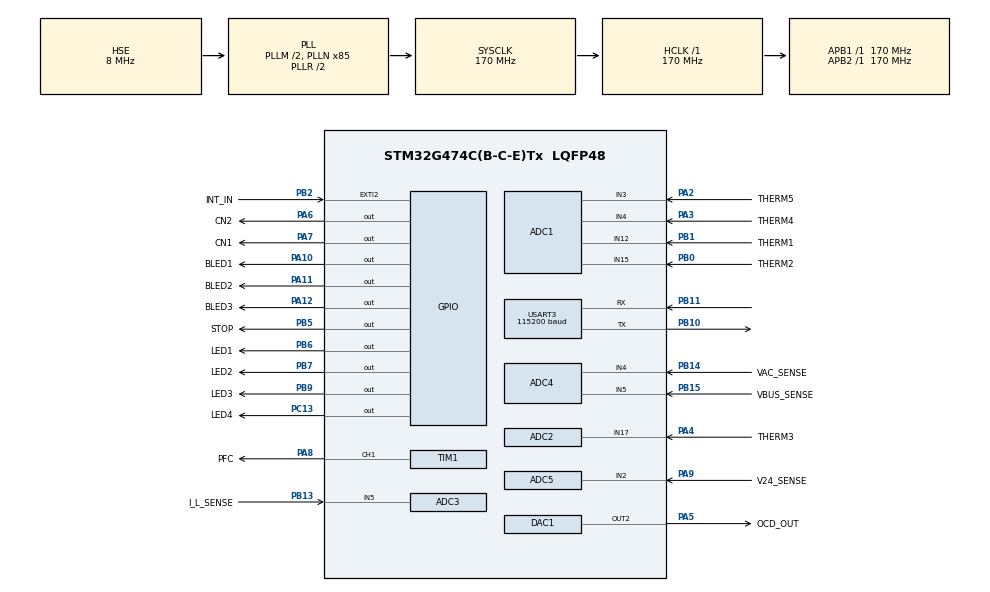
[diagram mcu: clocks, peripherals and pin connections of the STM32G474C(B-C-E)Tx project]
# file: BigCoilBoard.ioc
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ADC1.Channel-1\#ChannelRegularConversion=ADC_CHANNEL_12
ADC1.Channel-2\#ChannelRegularConversion=ADC_CHANNEL_15
ADC1.Channel-3\#ChannelRegularConversion=ADC_CHANNEL_4
ADC1.Channel-4\#ChannelRegularConversion=ADC_CHANNEL_3
ADC1.DMAContinuousRequests=ENABLE
ADC1.EOCSelection=ADC_EOC_SEQ_CONV
ADC1.ExternalTrigConv=ADC_EXTERNALTRIG_T6_TRGO
ADC1.NbrOfConversion=4
ADC1.NbrOfConversionFlag=1
ADC1.OffsetNumber-1\#ChannelRegularConversion=ADC_OFFSET_NONE
ADC1.OffsetNumber-2\#ChannelRegularConversion=ADC_OFFSET_NONE
ADC1.OffsetNumber-3\#ChannelRegularConversion=ADC_OFFSET_NONE
ADC1.OffsetNumber-4\#ChannelRegularConversion=ADC_OFFSET_NONE
ADC1.Rank-1\#ChannelRegularConversion=1
ADC1.Rank-2\#ChannelRegularConversion=2
ADC1.Rank-3\#ChannelRegularConversion=3
ADC1.Rank-4\#ChannelRegularConversion=4
ADC1.SamplingTime-1\#ChannelRegularConversion=ADC_SAMPLETIME_640CYCLES_5
ADC1.SamplingTime-2\#ChannelRegularConversion=ADC_SAMPLETIME_640CYCLES_5
ADC1.SamplingTime-3\#ChannelRegularConversion=ADC_SAMPLETIME_640CYCLES_5
ADC1.SamplingTime-4\#ChannelRegularConversion=ADC_SAMPLETIME_640CYCLES_5
ADC1.master=1
ADC2.Channel-2\#ChannelRegularConversion=ADC_CHANNEL_17
ADC2.DMAContinuousRequests=ENABLE
ADC2.ExternalTrigConv=ADC_EXTERNALTRIG_T6_TRGO
ADC2.NbrOfConversionFlag=1
ADC2.OffsetNumber-2\#ChannelRegularConversion=ADC_OFFSET_NONE
ADC2.Rank-2\#ChannelRegularConversion=1
ADC2.SamplingTime-2\#ChannelRegularConversion=ADC_SAMPLETIME_640CYCLES_5
ADC3.Channel-1\#ChannelRegularConversion=ADC_CHANNEL_5
ADC3.DMAContinuousRequests=ENABLE
ADC3.ExternalTrigConv=ADC_EXTERNALTRIG_T1_TRGO2
ADC3.NbrOfConversionFlag=1
ADC3.OffsetNumber-1\#ChannelRegularConversion=ADC_OFFSET_NONE
ADC3.Rank-1\#ChannelRegularConversion=1
ADC3.SamplingTime-1\#ChannelRegularConversion=ADC_SAMPLETIME_247CYCLES_5
ADC3.master=1
ADC4.Channel-1\#ChannelRegularConversion=ADC_CHANNEL_4
ADC4.Channel-2\#ChannelRegularConversion=ADC_CHANNEL_5
ADC4.DMAContinuousRequests=ENABLE
ADC4.ExternalTrigConv=ADC_EXTERNALTRIG_T1_TRGO2
ADC4.NbrOfConversion=2
ADC4.NbrOfConversionFlag=1
ADC4.OffsetNumber-1\#ChannelRegularConversion=ADC_OFFSET_NONE
ADC4.OffsetNumber-2\#ChannelRegularConversion=ADC_OFFSET_NONE
ADC4.Rank-1\#ChannelRegularConversion=1
ADC4.Rank-2\#ChannelRegularConversion=2
ADC4.SamplingTime-1\#ChannelRegularConversion=ADC_SAMPLETIME_247CYCLES_5
ADC4.SamplingTime-2\#ChannelRegularConversion=ADC_SAMPLETIME_247CYCLES_5
ADC5.Channel-0\#ChannelRegularConversion=ADC_CHANNEL_2
ADC5.Channel-1\#ChannelRegularConversion=ADC_CHANNEL_TEMPSENSOR_ADC5
ADC5.Channel-2\#ChannelRegularConversion=ADC_CHANNEL_VREFINT
ADC5.DMAContinuousRequests=ENABLE
ADC5.EOCSelection=ADC_EOC_SEQ_CONV
ADC5.ExternalTrigConv=ADC_EXTERNALTRIG_T6_TRGO
ADC5.NbrOfConversion=3
ADC5.NbrOfConversionFlag=1
ADC5.OffsetNumber-0\#ChannelRegularConversion=ADC_OFFSET_NONE
ADC5.OffsetNumber-1\#ChannelRegularConversion=ADC_OFFSET_NONE
ADC5.OffsetNumber-2\#ChannelRegularConversion=ADC_OFFSET_NONE
ADC5.Rank-0\#ChannelRegularConversion=1
ADC5.Rank-1\#ChannelRegularConversion=2
ADC5.Rank-2\#ChannelRegularConversion=3
ADC5.SamplingTime-0\#ChannelRegularConversion=ADC_SAMPLETIME_640CYCLES_5
ADC5.SamplingTime-1\#ChannelRegularConversion=ADC_SAMPLETIME_640CYCLES_5
ADC5.SamplingTime-2\#ChannelRegularConversion=ADC_SAMPLETIME_640CYCLES_5
COMP5.TriggerMode=COMP_TRIGGERMODE_IT_RISING
DAC1.DAC_Channel-DAC_OUT2=DAC_CHANNEL_2
DAC1.DAC_Trigger_OUT2-DAC_OUT2=DAC_TRIGGER_NONE
Dma.ADC1.0.Direction=DMA_PERIPH_TO_MEMORY
Dma.ADC1.0.EventEnable=DISABLE
Dma.ADC1.0.Instance=DMA1_Channel1
Dma.ADC1.0.MemDataAlignment=DMA_MDATAALIGN_HALFWORD
Dma.ADC1.0.MemInc=DMA_MINC_ENABLE
Dma.ADC1.0.Mode=DMA_CIRCULAR
Dma.ADC1.0.PeriphDataAlignment=DMA_PDATAALIGN_HALFWORD
Dma.ADC1.0.PeriphInc=DMA_PINC_DISABLE
Dma.ADC1.0.Polarity=HAL_DMAMUX_REQ_GEN_RISING
Dma.ADC1.0.Priority=DMA_PRIORITY_LOW
Dma.ADC1.0.RequestNumber=1
Dma.ADC1.0.SignalID=NONE
Dma.ADC1.0.SyncEnable=DISABLE
Dma.ADC1.0.SyncPolarity=HAL_DMAMUX_SYNC_NO_EVENT
Dma.ADC1.0.SyncRequestNumber=1
Dma.ADC1.0.SyncSignalID=NONE
Dma.ADC2.2.Direction=DMA_PERIPH_TO_MEMORY
Dma.ADC2.2.EventEnable=DISABLE
Dma.ADC2.2.Instance=DMA1_Channel2
Dma.ADC2.2.MemDataAlignment=DMA_MDATAALIGN_HALFWORD
Dma.ADC2.2.MemInc=DMA_MINC_ENABLE
Dma.ADC2.2.Mode=DMA_CIRCULAR
Dma.ADC2.2.PeriphDataAlignment=DMA_PDATAALIGN_HALFWORD
Dma.ADC2.2.PeriphInc=DMA_PINC_DISABLE
Dma.ADC2.2.Polarity=HAL_DMAMUX_REQ_GEN_RISING
Dma.ADC2.2.Priority=DMA_PRIORITY_LOW
Dma.ADC2.2.RequestNumber=1
Dma.ADC2.2.SignalID=NONE
Dma.ADC2.2.SyncEnable=DISABLE
Dma.ADC2.2.SyncPolarity=HAL_DMAMUX_SYNC_NO_EVENT
Dma.ADC2.2.SyncRequestNumber=1
Dma.ADC2.2.SyncSignalID=NONE
Dma.ADC3.3.Direction=DMA_PERIPH_TO_MEMORY
Dma.ADC3.3.EventEnable=DISABLE
Dma.ADC3.3.Instance=DMA1_Channel3
Dma.ADC3.3.MemDataAlignment=DMA_MDATAALIGN_HALFWORD
Dma.ADC3.3.MemInc=DMA_MINC_ENABLE
Dma.ADC3.3.Mode=DMA_CIRCULAR
Dma.ADC3.3.PeriphDataAlignment=DMA_PDATAALIGN_HALFWORD
Dma.ADC3.3.PeriphInc=DMA_PINC_DISABLE
Dma.ADC3.3.Polarity=HAL_DMAMUX_REQ_GEN_RISING
Dma.ADC3.3.Priority=DMA_PRIORITY_LOW
Dma.ADC3.3.RequestNumber=1
Dma.ADC3.3.SignalID=NONE
Dma.ADC3.3.SyncEnable=DISABLE
Dma.ADC3.3.SyncPolarity=HAL_DMAMUX_SYNC_NO_EVENT
Dma.ADC3.3.SyncRequestNumber=1
Dma.ADC3.3.SyncSignalID=NONE
Dma.ADC4.4.Direction=DMA_PERIPH_TO_MEMORY
Dma.ADC4.4.EventEnable=DISABLE
Dma.ADC4.4.Instance=DMA1_Channel4
Dma.ADC4.4.MemDataAlignment=DMA_MDATAALIGN_HALFWORD
Dma.ADC4.4.MemInc=DMA_MINC_ENABLE
Dma.ADC4.4.Mode=DMA_CIRCULAR
Dma.ADC4.4.PeriphDataAlignment=DMA_PDATAALIGN_HALFWORD
Dma.ADC4.4.PeriphInc=DMA_PINC_DISABLE
Dma.ADC4.4.Polarity=HAL_DMAMUX_REQ_GEN_RISING
Dma.ADC4.4.Priority=DMA_PRIORITY_LOW
Dma.ADC4.4.RequestNumber=1
Dma.ADC4.4.SignalID=NONE
Dma.ADC4.4.SyncEnable=DISABLE
Dma.ADC4.4.SyncPolarity=HAL_DMAMUX_SYNC_NO_EVENT
Dma.ADC4.4.SyncRequestNumber=1
Dma.ADC4.4.SyncSignalID=NONE
Dma.ADC5.1.Direction=DMA_PERIPH_TO_MEMORY
Dma.ADC5.1.EventEnable=DISABLE
Dma.ADC5.1.Instance=DMA1_Channel6
Dma.ADC5.1.MemDataAlignment=DMA_MDATAALIGN_HALFWORD
Dma.ADC5.1.MemInc=DMA_MINC_ENABLE
Dma.ADC5.1.Mode=DMA_CIRCULAR
Dma.ADC5.1.PeriphDataAlignment=DMA_PDATAALIGN_HALFWORD
Dma.ADC5.1.PeriphInc=DMA_PINC_DISABLE
Dma.ADC5.1.Polarity=HAL_DMAMUX_REQ_GEN_RISING
Dma.ADC5.1.Priority=DMA_PRIORITY_LOW
Dma.ADC5.1.RequestNumber=1
Dma.ADC5.1.SignalID=NONE
Dma.ADC5.1.SyncEnable=DISABLE
Dma.ADC5.1.SyncPolarity=HAL_DMAMUX_SYNC_NO_EVENT
Dma.ADC5.1.SyncRequestNumber=1
Dma.ADC5.1.SyncSignalID=NONE
Dma.Request0=ADC1
Dma.Request1=ADC5
Dma.Request2=ADC2
Dma.Request3=ADC3
Dma.Request4=ADC4
Mcu.Family=STM32G4
Mcu.Name=STM32G474C(B-C-E)Tx
Mcu.Package=LQFP48
NVIC.ADC1_2_IRQn=true\:0\:0\:true\:false\:true\:true\:true\:true
NVIC.ADC3_IRQn=true\:0\:0\:true\:false\:true\:true\:true\:true
NVIC.ADC4_IRQn=true\:0\:0\:false\:false\:true\:true\:true\:true
NVIC.ADC5_IRQn=true\:0\:0\:false\:false\:true\:true\:true\:true
NVIC.COMP4_5_6_IRQn=true\:0\:0\:false\:false\:true\:false\:true\:true
NVIC.DMA1_Channel1_IRQn=true\:0\:0\:false\:false\:true\:false\:true\:true
NVIC.DMA1_Channel2_IRQn=true\:0\:0\:false\:false\:true\:false\:true\:true
NVIC.DMA1_Channel3_IRQn=true\:0\:0\:false\:false\:true\:false\:true\:true
NVIC.DMA1_Channel4_IRQn=true\:0\:0\:false\:false\:true\:false\:true\:true
NVIC.DMA1_Channel6_IRQn=true\:0\:0\:false\:false\:true\:false\:true\:true
NVIC.EXTI2_IRQn=true\:0\:0\:false\:false\:true\:true\:true\:true
NVIC.FLASH_IRQn=true\:0\:0\:false\:false\:true\:true\:true\:true
NVIC.FPU_IRQn=true\:0\:0\:false\:false\:true\:true\:false\:true
NVIC.PriorityGroup=NVIC_PRIORITYGROUP_4
NVIC.RCC_IRQn=true\:0\:0\:false\:false\:true\:true\:false\:true
NVIC.TIM1_BRK_TIM15_IRQn=true\:0\:0\:true\:false\:true\:true\:true\:true
NVIC.TIM1_CC_IRQn=true\:0\:0\:true\:false\:true\:true\:true\:true
NVIC.TIM1_TRG_COM_TIM17_IRQn=true\:0\:0\:true\:false\:true\:true\:true\:true
NVIC.TIM1_UP_TIM16_IRQn=true\:0\:0\:true\:false\:true\:true\:true\:true
NVIC.TIM2_IRQn=true\:0\:0\:true\:false\:true\:true\:true\:true
NVIC.TIM6_DAC_IRQn=true\:0\:0\:true\:false\:true\:true\:true\:true
NVIC.TIM7_DAC_IRQn=true\:0\:0\:true\:false\:true\:true\:true\:true
NVIC.USART3_IRQn=true\:0\:0\:true\:false\:true\:true\:true\:true
PA10.GPIO_Label=BLED1
PA10.Signal=GPIO_Output
PA11.GPIO_Label=BLED2
PA11.Signal=GPIO_Output
PA12.GPIO_Label=BLED3
PA12.Signal=GPIO_Output
PA13.Mode=JTAG_4_pins
PA13.Signal=SYS_JTMS-SWDIO
PA14.Mode=JTAG_4_pins
PA14.Signal=SYS_JTCK-SWCLK
PA15.Mode=JTAG_4_pins
PA15.Signal=SYS_JTDI
PA2.GPIO_Label=THERM5
PA2.Mode=IN3-Single-Ended
PA2.Signal=ADC1_IN3
PA3.GPIO_Label=THERM4
PA3.Mode=IN4-Single-Ended
PA3.Signal=ADC1_IN4
PA4.GPIO_Label=THERM3
PA4.Mode=IN17-Single-Ended
PA4.Signal=ADC2_IN17
PA5.GPIO_Label=OCD_OUT
PA5.Signal=COMP_DAC12_group
PA6.GPIO_Label=CN2
PA6.Signal=GPIO_Output
PA7.GPIO_Label=CN1
PA7.Signal=GPIO_Output
PA8.GPIO_Label=PFC
PA8.Signal=S_TIM1_CH1
PA9.GPIO_Label=V24_SENSE
PA9.Mode=IN2-Single-Ended
PA9.Signal=ADC5_IN2
PB0.GPIO_Label=THERM2
PB0.Mode=IN15-Single-Ended
PB0.Signal=ADC1_IN15
PB1.GPIO_Label=THERM1
PB1.Mode=IN12-Single-Ended
PB1.Signal=ADC1_IN12
PB10.Mode=Asynchronous
PB10.Signal=USART3_TX
PB11.Mode=Asynchronous
PB11.Signal=USART3_RX
PB13.GPIO_Label=I_L_SENSE
PB13.Signal=SharedAnalog_PB13
PB14.GPIO_Label=VAC_SENSE
PB14.Mode=IN4-Single-Ended
PB14.Signal=ADC4_IN4
PB15.GPIO_Label=VBUS_SENSE
PB15.Mode=IN5-Single-Ended
PB15.Signal=ADC4_IN5
PB2.GPIO_Label=INT_IN
PB2.Signal=GPXTI2
PB3.Mode=JTAG_4_pins
PB3.Signal=SYS_JTDO-SWO
PB4.Signal=SYS_JTRST
PB5.GPIO_Label=STOP
PB5.Signal=GPIO_Output
PB6.GPIO_Label=LED1
PB6.Signal=GPIO_Output
PB7.GPIO_Label=LED2
PB7.Signal=GPIO_Output
PB9.GPIO_Label=LED3
PB9.Signal=GPIO_Output
PC13.GPIO_Label=LED4
PC13.Signal=GPIO_Output
PF0-OSC_IN.Mode=HSE-External-Oscillator
PF0-OSC_IN.Signal=RCC_OSC_IN
PF1-OSC_OUT.Mode=HSE-External-Oscillator
PF1-OSC_OUT.Signal=RCC_OSC_OUT
ProjectManager.HeapSize=0x200
ProjectManager.StackSize=0x400
ProjectManager.TargetToolchain=STM32CubeIDE
RCC.ADC12Freq_Value=170000000
RCC.ADC345Freq_Value=170000000
RCC.AHBFreq_Value=170000000
RCC.APB1Freq_Value=170000000
RCC.APB1TimFreq_Value=170000000
RCC.APB2Freq_Value=170000000
RCC.APB2TimFreq_Value=170000000
RCC.CortexFreq_Value=170000000
RCC.EXTERNAL_CLOCK_VALUE=12288000
RCC.HCLKFreq_Value=170000000
RCC.HSE_VALUE=8000000
RCC.HSI48_VALUE=48000000
RCC.HSI_VALUE=16000000
RCC.LSE_VALUE=32768
RCC.PLLM=RCC_PLLM_DIV2
RCC.PLLN=85
RCC.PLLSourceVirtual=RCC_PLLSOURCE_HSE
RCC.SYSCLKFreq_VALUE=170000000
RCC.SYSCLKSource=RCC_SYSCLKSOURCE_PLLCLK
RCC.USBFreq_Value=170000000
RCC.VCOOutputFreq_Value=340000000
SH.COMP_DAC12_group.0=DAC1_OUT2,DAC_OUT2
SH.S_TIM1_CH1.0=TIM1_CH1,PWM Generation1 CH1
SH.SharedAnalog_PB13.0=ADC3_IN5,IN5-Single-Ended
SH.SharedAnalog_PB13.1=COMP5_INP,INP
TIM1.BreakState=TIM_BREAK_DISABLE
TIM1.Channel-PWM\ Generation1\ CH1=TIM_CHANNEL_1
TIM1.Channel-PWM\ Generation5\ No\ Output=TIM_CHANNEL_5
TIM1.CounterMode=TIM_COUNTERMODE_CENTERALIGNED1
TIM1.PeriodNoDither=9444
TIM1.PulseNoDither_5=1
TIM1.SourceBRKCOMP5=TIM_BREAKINPUTSOURCE_ENABLE
TIM1.TIM_MasterOutputTrigger=TIM_TRGO_UPDATE
TIM1.TIM_MasterOutputTrigger2=TIM_TRGO2_OC5REF
TIM16.Prescaler=170
TIM2.Prescaler=0
TIM2.TIM_MasterOutputTrigger=TIM_TRGO_UPDATE
TIM6.PeriodNoDither=10000
TIM6.Prescaler=170
TIM6.TIM_MasterOutputTrigger=TIM_TRGO_UPDATE
TIM7.PeriodNoDither=1360
TIM7.Prescaler=50000
TIM7.TIM_MasterOutputTrigger=TIM_TRGO_UPDATE
USART3.BaudRate=115200
USART3.RxPinLevelInvertParam=ADVFEATURE_RXINV_DISABLE
USART3.VirtualMode-Asynchronous=VM_ASYNC
VP_ADC5_TempSens_Input.Mode=IN-TempSens
VP_ADC5_Vref_Input.Mode=IN-Vrefint
VP_COMP5_VS_DAC4OUT1.Mode=INM_DAC4OUT1
VP_DAC4_VS_DACI1.Mode=DAC_OUT1_Int
VP_SYS_VS_DBSignals.Mode=DisableDeadBatterySignals
VP_SYS_V_VREFBUF.Mode=ExternalMode
VP_TIM16_VS_ClockSourceINT.Mode=Enable_Timer
VP_TIM1_VS_ClockSourceINT.Mode=Internal
VP_TIM1_VS_no_output5.Mode=PWM Generation5 No Output
VP_TIM2_VS_ClockSourceINT.Mode=Internal
VP_TIM6_VS_ClockSourceINT.Mode=Enable_Timer
VP_TIM7_VS_ClockSourceINT.Mode=Enable_Timer
board=custom

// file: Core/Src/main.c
/* USER CODE BEGIN Header */
/**
  ******************************************************************************
  * @file           : main.c
  * @brief          : Main program body
  ******************************************************************************
  * @attention
  *
  * Copyright (c) 2025 STMicroelectronics.
  * All rights reserved.
  *
  * This software is licensed under terms that can be found in the LICENSE file
  * in the root directory of this software component.
  * If no LICENSE file comes with this software, it is provided AS-IS.
  *
  ******************************************************************************
  */
/* USER CODE END Header */
#include "main.h"

ADC_HandleTypeDef hadc1;
ADC_HandleTypeDef hadc2;
ADC_HandleTypeDef hadc3;
ADC_HandleTypeDef hadc4;
ADC_HandleTypeDef hadc5;
DMA_HandleTypeDef hdma_adc1;
DMA_HandleTypeDef hdma_adc2;
DMA_HandleTypeDef hdma_adc3;
DMA_HandleTypeDef hdma_adc4;
DMA_HandleTypeDef hdma_adc5;

COMP_HandleTypeDef hcomp5;

DAC_HandleTypeDef hdac1;
DAC_HandleTypeDef hdac4;

TIM_HandleTypeDef htim1;
TIM_HandleTypeDef htim2;
TIM_HandleTypeDef htim6;
TIM_HandleTypeDef htim7;
TIM_HandleTypeDef htim16;

UART_HandleTypeDef huart3;

void SystemClock_Config(void);
static void MX_GPIO_Init(void);
static void MX_DMA_Init(void);
static void MX_DAC1_Init(void);
static void MX_USART3_UART_Init(void);
static void MX_TIM6_Init(void);
static void MX_TIM7_Init(void);
static void MX_TIM1_Init(void);
static void MX_ADC1_Init(void);
static void MX_TIM2_Init(void);
static void MX_TIM16_Init(void);
static void MX_ADC5_Init(void);
static void MX_ADC2_Init(void);
static void MX_DAC4_Init(void);
static void MX_ADC3_Init(void);
static void MX_ADC4_Init(void);
static void MX_COMP5_Init(void);

int main(void)
{

  /* MCU Configuration--------------------------------------------------------*/

  /* Reset of all peripherals, Initializes the Flash interface and the Systick. */
  HAL_Init();

  /* Configure the system clock */
  SystemClock_Config();

  /* Initialize all configured peripherals */
  MX_GPIO_Init();
  MX_DMA_Init();
  MX_DAC1_Init();
  MX_USART3_UART_Init();
  MX_TIM6_Init();
  MX_TIM7_Init();
  MX_TIM1_Init();
  MX_ADC1_Init();
  MX_TIM2_Init();
  MX_TIM16_Init();
  MX_ADC5_Init();
  MX_ADC2_Init();
  MX_DAC4_Init();
  MX_ADC3_Init();
  MX_ADC4_Init();
  MX_COMP5_Init();
  /* USER CODE BEGIN 2 */
  TC_Init();
  /* USER CODE END 2 */

  /* Infinite loop */
  while (1)
  {

    /* USER CODE BEGIN 3 */
	  TC_Loop();
  }
  /* USER CODE END 3 */
}

void SystemClock_Config(void)
{
  RCC_OscInitTypeDef RCC_OscInitStruct = {0};
  RCC_ClkInitTypeDef RCC_ClkInitStruct = {0};

  /** Configure the main internal regulator output voltage
  */
  HAL_PWREx_ControlVoltageScaling(PWR_REGULATOR_VOLTAGE_SCALE1_BOOST);

  /** Initializes the RCC Oscillators according to the specified parameters
  * in the RCC_OscInitTypeDef structure.
  */
  RCC_OscInitStruct.OscillatorType = RCC_OSCILLATORTYPE_HSE;
  RCC_OscInitStruct.HSEState = RCC_HSE_ON;
  RCC_OscInitStruct.PLL.PLLState = RCC_PLL_ON;
  RCC_OscInitStruct.PLL.PLLSource = RCC_PLLSOURCE_HSE;
  RCC_OscInitStruct.PLL.PLLM = RCC_PLLM_DIV2;
  RCC_OscInitStruct.PLL.PLLN = 85;
  RCC_OscInitStruct.PLL.PLLP = RCC_PLLP_DIV2;
  RCC_OscInitStruct.PLL.PLLQ = RCC_PLLQ_DIV2;
  RCC_OscInitStruct.PLL.PLLR = RCC_PLLR_DIV2;
  if (HAL_RCC_OscConfig(&RCC_OscInitStruct) != HAL_OK)
  {
    Error_Handler();
  }

  /** Initializes the CPU, AHB and APB buses clocks
  */
  RCC_ClkInitStruct.ClockType = RCC_CLOCKTYPE_HCLK|RCC_CLOCKTYPE_SYSCLK
                              |RCC_CLOCKTYPE_PCLK1|RCC_CLOCKTYPE_PCLK2;
  RCC_ClkInitStruct.SYSCLKSource = RCC_SYSCLKSOURCE_PLLCLK;
  RCC_ClkInitStruct.AHBCLKDivider = RCC_SYSCLK_DIV1;
  RCC_ClkInitStruct.APB1CLKDivider = RCC_HCLK_DIV1;
  RCC_ClkInitStruct.APB2CLKDivider = RCC_HCLK_DIV1;

  if (HAL_RCC_ClockConfig(&RCC_ClkInitStruct, FLASH_LATENCY_4) != HAL_OK)
  {
    Error_Handler();
  }
}

static void MX_ADC1_Init(void)
{

  ADC_MultiModeTypeDef multimode = {0};
  ADC_ChannelConfTypeDef sConfig = {0};

  /** Common config
  */
  hadc1.Instance = ADC1;
  hadc1.Init.ClockPrescaler = ADC_CLOCK_SYNC_PCLK_DIV4;
  hadc1.Init.Resolution = ADC_RESOLUTION_12B;
  hadc1.Init.DataAlign = ADC_DATAALIGN_RIGHT;
  hadc1.Init.GainCompensation = 0;
  hadc1.Init.ScanConvMode = ADC_SCAN_ENABLE;
  hadc1.Init.EOCSelection = ADC_EOC_SEQ_CONV;
  hadc1.Init.LowPowerAutoWait = DISABLE;
  hadc1.Init.ContinuousConvMode = DISABLE;
  hadc1.Init.NbrOfConversion = 4;
  hadc1.Init.DiscontinuousConvMode = DISABLE;
  hadc1.Init.ExternalTrigConv = ADC_EXTERNALTRIG_T6_TRGO;
  hadc1.Init.ExternalTrigConvEdge = ADC_EXTERNALTRIGCONVEDGE_RISING;
  hadc1.Init.DMAContinuousRequests = ENABLE;
  hadc1.Init.Overrun = ADC_OVR_DATA_PRESERVED;
  hadc1.Init.OversamplingMode = DISABLE;
  if (HAL_ADC_Init(&hadc1) != HAL_OK)
  {
    Error_Handler();
  }

  /** Configure the ADC multi-mode
  */
  multimode.Mode = ADC_MODE_INDEPENDENT;
  if (HAL_ADCEx_MultiModeConfigChannel(&hadc1, &multimode) != HAL_OK)
  {
    Error_Handler();
  }

  /** Configure Regular Channel
  */
  sConfig.Channel = ADC_CHANNEL_12;
  sConfig.Rank = ADC_REGULAR_RANK_1;
  sConfig.SamplingTime = ADC_SAMPLETIME_640CYCLES_5;
  sConfig.SingleDiff = ADC_SINGLE_ENDED;
  sConfig.OffsetNumber = ADC_OFFSET_NONE;
  sConfig.Offset = 0;
  if (HAL_ADC_ConfigChannel(&hadc1, &sConfig) != HAL_OK)
  {
    Error_Handler();
  }

  /** Configure Regular Channel
  */
  sConfig.Channel = ADC_CHANNEL_15;
  sConfig.Rank = ADC_REGULAR_RANK_2;
  if (HAL_ADC_ConfigChannel(&hadc1, &sConfig) != HAL_OK)
  {
    Error_Handler();
  }

  /** Configure Regular Channel
  */
  sConfig.Channel = ADC_CHANNEL_4;
  sConfig.Rank = ADC_REGULAR_RANK_3;
  if (HAL_ADC_ConfigChannel(&hadc1, &sConfig) != HAL_OK)
  {
    Error_Handler();
  }

  /** Configure Regular Channel
  */
  sConfig.Channel = ADC_CHANNEL_3;
  sConfig.Rank = ADC_REGULAR_RANK_4;
  if (HAL_ADC_ConfigChannel(&hadc1, &sConfig) != HAL_OK)
  {
    Error_Handler();
  }

}

static void MX_ADC2_Init(void)
{

  ADC_ChannelConfTypeDef sConfig = {0};

  /** Common config
  */
  hadc2.Instance = ADC2;
  hadc2.Init.ClockPrescaler = ADC_CLOCK_SYNC_PCLK_DIV4;
  hadc2.Init.Resolution = ADC_RESOLUTION_12B;
  hadc2.Init.DataAlign = ADC_DATAALIGN_RIGHT;
  hadc2.Init.GainCompensation = 0;
  hadc2.Init.ScanConvMode = ADC_SCAN_DISABLE;
  hadc2.Init.EOCSelection = ADC_EOC_SINGLE_CONV;
  hadc2.Init.LowPowerAutoWait = DISABLE;
  hadc2.Init.ContinuousConvMode = DISABLE;
  hadc2.Init.NbrOfConversion = 1;
  hadc2.Init.DiscontinuousConvMode = DISABLE;
  hadc2.Init.ExternalTrigConv = ADC_EXTERNALTRIG_T6_TRGO;
  hadc2.Init.ExternalTrigConvEdge = ADC_EXTERNALTRIGCONVEDGE_RISING;
  hadc2.Init.DMAContinuousRequests = ENABLE;
  hadc2.Init.Overrun = ADC_OVR_DATA_PRESERVED;
  hadc2.Init.OversamplingMode = DISABLE;
  if (HAL_ADC_Init(&hadc2) != HAL_OK)
  {
    Error_Handler();
  }

  /** Configure Regular Channel
  */
  sConfig.Channel = ADC_CHANNEL_17;
  sConfig.Rank = ADC_REGULAR_RANK_1;
  sConfig.SamplingTime = ADC_SAMPLETIME_640CYCLES_5;
  sConfig.SingleDiff = ADC_SINGLE_ENDED;
  sConfig.OffsetNumber = ADC_OFFSET_NONE;
  sConfig.Offset = 0;
  if (HAL_ADC_ConfigChannel(&hadc2, &sConfig) != HAL_OK)
  {
    Error_Handler();
  }

}

static void MX_ADC3_Init(void)
{

  ADC_MultiModeTypeDef multimode = {0};
  ADC_ChannelConfTypeDef sConfig = {0};

  /** Common config
  */
  hadc3.Instance = ADC3;
  hadc3.Init.ClockPrescaler = ADC_CLOCK_SYNC_PCLK_DIV4;
  hadc3.Init.Resolution = ADC_RESOLUTION_12B;
  hadc3.Init.DataAlign = ADC_DATAALIGN_RIGHT;
  hadc3.Init.GainCompensation = 0;
  hadc3.Init.ScanConvMode = ADC_SCAN_DISABLE;
  hadc3.Init.EOCSelection = ADC_EOC_SINGLE_CONV;
  hadc3.Init.LowPowerAutoWait = DISABLE;
  hadc3.Init.ContinuousConvMode = DISABLE;
  hadc3.Init.NbrOfConversion = 1;
  hadc3.Init.DiscontinuousConvMode = DISABLE;
  hadc3.Init.ExternalTrigConv = ADC_EXTERNALTRIG_T1_TRGO2;
  hadc3.Init.ExternalTrigConvEdge = ADC_EXTERNALTRIGCONVEDGE_RISING;
  hadc3.Init.DMAContinuousRequests = ENABLE;
  hadc3.Init.Overrun = ADC_OVR_DATA_PRESERVED;
  hadc3.Init.OversamplingMode = DISABLE;
  if (HAL_ADC_Init(&hadc3) != HAL_OK)
  {
    Error_Handler();
  }

  /** Configure the ADC multi-mode
  */
  multimode.Mode = ADC_MODE_INDEPENDENT;
  if (HAL_ADCEx_MultiModeConfigChannel(&hadc3, &multimode) != HAL_OK)
  {
    Error_Handler();
  }

  /** Configure Regular Channel
  */
  sConfig.Channel = ADC_CHANNEL_5;
  sConfig.Rank = ADC_REGULAR_RANK_1;
  sConfig.SamplingTime = ADC_SAMPLETIME_247CYCLES_5;
  sConfig.SingleDiff = ADC_SINGLE_ENDED;
  sConfig.OffsetNumber = ADC_OFFSET_NONE;
  sConfig.Offset = 0;
  if (HAL_ADC_ConfigChannel(&hadc3, &sConfig) != HAL_OK)
  {
    Error_Handler();
  }

}

static void MX_ADC4_Init(void)
{

  ADC_ChannelConfTypeDef sConfig = {0};

  /** Common config
  */
  hadc4.Instance = ADC4;
  hadc4.Init.ClockPrescaler = ADC_CLOCK_SYNC_PCLK_DIV4;
  hadc4.Init.Resolution = ADC_RESOLUTION_12B;
  hadc4.Init.DataAlign = ADC_DATAALIGN_RIGHT;
  hadc4.Init.GainCompensation = 0;
  hadc4.Init.ScanConvMode = ADC_SCAN_ENABLE;
  hadc4.Init.EOCSelection = ADC_EOC_SINGLE_CONV;
  hadc4.Init.LowPowerAutoWait = DISABLE;
  hadc4.Init.ContinuousConvMode = DISABLE;
  hadc4.Init.NbrOfConversion = 2;
  hadc4.Init.DiscontinuousConvMode = DISABLE;
  hadc4.Init.ExternalTrigConv = ADC_EXTERNALTRIG_T1_TRGO2;
  hadc4.Init.ExternalTrigConvEdge = ADC_EXTERNALTRIGCONVEDGE_RISING;
  hadc4.Init.DMAContinuousRequests = ENABLE;
  hadc4.Init.Overrun = ADC_OVR_DATA_PRESERVED;
  hadc4.Init.OversamplingMode = DISABLE;
  if (HAL_ADC_Init(&hadc4) != HAL_OK)
  {
    Error_Handler();
  }

  /** Configure Regular Channel
  */
  sConfig.Channel = ADC_CHANNEL_4;
  sConfig.Rank = ADC_REGULAR_RANK_1;
  sConfig.SamplingTime = ADC_SAMPLETIME_247CYCLES_5;
  sConfig.SingleDiff = ADC_SINGLE_ENDED;
  sConfig.OffsetNumber = ADC_OFFSET_NONE;
  sConfig.Offset = 0;
  if (HAL_ADC_ConfigChannel(&hadc4, &sConfig) != HAL_OK)
  {
    Error_Handler();
  }

  /** Configure Regular Channel
  */
  sConfig.Channel = ADC_CHANNEL_5;
  sConfig.Rank = ADC_REGULAR_RANK_2;
  if (HAL_ADC_ConfigChannel(&hadc4, &sConfig) != HAL_OK)
  {
    Error_Handler();
  }

}

static void MX_ADC5_Init(void)
{

  ADC_ChannelConfTypeDef sConfig = {0};

  /** Common config
  */
  hadc5.Instance = ADC5;
  hadc5.Init.ClockPrescaler = ADC_CLOCK_SYNC_PCLK_DIV4;
  hadc5.Init.Resolution = ADC_RESOLUTION_12B;
  hadc5.Init.DataAlign = ADC_DATAALIGN_RIGHT;
  hadc5.Init.GainCompensation = 0;
  hadc5.Init.ScanConvMode = ADC_SCAN_ENABLE;
  hadc5.Init.EOCSelection = ADC_EOC_SEQ_CONV;
  hadc5.Init.LowPowerAutoWait = DISABLE;
  hadc5.Init.ContinuousConvMode = DISABLE;
  hadc5.Init.NbrOfConversion = 3;
  hadc5.Init.DiscontinuousConvMode = DISABLE;
  hadc5.Init.ExternalTrigConv = ADC_EXTERNALTRIG_T6_TRGO;
  hadc5.Init.ExternalTrigConvEdge = ADC_EXTERNALTRIGCONVEDGE_RISING;
  hadc5.Init.DMAContinuousRequests = ENABLE;
  hadc5.Init.Overrun = ADC_OVR_DATA_PRESERVED;
  hadc5.Init.OversamplingMode = DISABLE;
  if (HAL_ADC_Init(&hadc5) != HAL_OK)
  {
    Error_Handler();
  }

  /** Configure Regular Channel
  */
  sConfig.Channel = ADC_CHANNEL_2;
  sConfig.Rank = ADC_REGULAR_RANK_1;
  sConfig.SamplingTime = ADC_SAMPLETIME_640CYCLES_5;
  sConfig.SingleDiff = ADC_SINGLE_ENDED;
  sConfig.OffsetNumber = ADC_OFFSET_NONE;
  sConfig.Offset = 0;
  if (HAL_ADC_ConfigChannel(&hadc5, &sConfig) != HAL_OK)
  {
    Error_Handler();
  }

  /** Configure Regular Channel
  */
  sConfig.Channel = ADC_CHANNEL_TEMPSENSOR_ADC5;
  sConfig.Rank = ADC_REGULAR_RANK_2;
  if (HAL_ADC_ConfigChannel(&hadc5, &sConfig) != HAL_OK)
  {
    Error_Handler();
  }

  /** Configure Regular Channel
  */
  sConfig.Channel = ADC_CHANNEL_VREFINT;
  sConfig.Rank = ADC_REGULAR_RANK_3;
  if (HAL_ADC_ConfigChannel(&hadc5, &sConfig) != HAL_OK)
  {
    Error_Handler();
  }

}

static void MX_COMP5_Init(void)
{

  hcomp5.Instance = COMP5;
  hcomp5.Init.InputPlus = COMP_INPUT_PLUS_IO1;
  hcomp5.Init.InputMinus = COMP_INPUT_MINUS_DAC4_CH1;
  hcomp5.Init.OutputPol = COMP_OUTPUTPOL_NONINVERTED;
  hcomp5.Init.Hysteresis = COMP_HYSTERESIS_NONE;
  hcomp5.Init.BlankingSrce = COMP_BLANKINGSRC_NONE;
  hcomp5.Init.TriggerMode = COMP_TRIGGERMODE_IT_RISING;
  if (HAL_COMP_Init(&hcomp5) != HAL_OK)
  {
    Error_Handler();
  }

}

static void MX_DAC1_Init(void)
{

  DAC_ChannelConfTypeDef sConfig = {0};

  /** DAC Initialization
  */
  hdac1.Instance = DAC1;
  if (HAL_DAC_Init(&hdac1) != HAL_OK)
  {
    Error_Handler();
  }

  /** DAC channel OUT2 config
  */
  sConfig.DAC_HighFrequency = DAC_HIGH_FREQUENCY_INTERFACE_MODE_AUTOMATIC;
  sConfig.DAC_DMADoubleDataMode = DISABLE;
  sConfig.DAC_SignedFormat = DISABLE;
  sConfig.DAC_SampleAndHold = DAC_SAMPLEANDHOLD_DISABLE;
  sConfig.DAC_Trigger = DAC_TRIGGER_NONE;
  sConfig.DAC_Trigger2 = DAC_TRIGGER_NONE;
  sConfig.DAC_OutputBuffer = DAC_OUTPUTBUFFER_ENABLE;
  sConfig.DAC_ConnectOnChipPeripheral = DAC_CHIPCONNECT_EXTERNAL;
  sConfig.DAC_UserTrimming = DAC_TRIMMING_FACTORY;
  if (HAL_DAC_ConfigChannel(&hdac1, &sConfig, DAC_CHANNEL_2) != HAL_OK)
  {
    Error_Handler();
  }

}

static void MX_DAC4_Init(void)
{

  DAC_ChannelConfTypeDef sConfig = {0};

  /** DAC Initialization
  */
  hdac4.Instance = DAC4;
  if (HAL_DAC_Init(&hdac4) != HAL_OK)
  {
    Error_Handler();
  }

  /** DAC channel OUT1 config
  */
  sConfig.DAC_HighFrequency = DAC_HIGH_FREQUENCY_INTERFACE_MODE_AUTOMATIC;
  sConfig.DAC_DMADoubleDataMode = DISABLE;
  sConfig.DAC_SignedFormat = DISABLE;
  sConfig.DAC_SampleAndHold = DAC_SAMPLEANDHOLD_DISABLE;
  sConfig.DAC_Trigger = DAC_TRIGGER_NONE;
  sConfig.DAC_Trigger2 = DAC_TRIGGER_NONE;
  sConfig.DAC_OutputBuffer = DAC_OUTPUTBUFFER_DISABLE;
  sConfig.DAC_ConnectOnChipPeripheral = DAC_CHIPCONNECT_INTERNAL;
  sConfig.DAC_UserTrimming = DAC_TRIMMING_FACTORY;
  if (HAL_DAC_ConfigChannel(&hdac4, &sConfig, DAC_CHANNEL_1) != HAL_OK)
  {
    Error_Handler();
  }

}

static void MX_TIM1_Init(void)
{

  TIM_ClockConfigTypeDef sClockSourceConfig = {0};
  TIM_MasterConfigTypeDef sMasterConfig = {0};
  TIMEx_BreakInputConfigTypeDef sBreakInputConfig = {0};
  TIM_OC_InitTypeDef sConfigOC = {0};
  TIM_BreakDeadTimeConfigTypeDef sBreakDeadTimeConfig = {0};

  htim1.Instance = TIM1;
  htim1.Init.Prescaler = 0;
  htim1.Init.CounterMode = TIM_COUNTERMODE_CENTERALIGNED1;
  htim1.Init.Period = 9444;
  htim1.Init.ClockDivision = TIM_CLOCKDIVISION_DIV1;
  htim1.Init.RepetitionCounter = 0;
  htim1.Init.AutoReloadPreload = TIM_AUTORELOAD_PRELOAD_DISABLE;
  if (HAL_TIM_Base_Init(&htim1) != HAL_OK)
  {
    Error_Handler();
  }
  sClockSourceConfig.ClockSource = TIM_CLOCKSOURCE_INTERNAL;
  if (HAL_TIM_ConfigClockSource(&htim1, &sClockSourceConfig) != HAL_OK)
  {
    Error_Handler();
  }
  if (HAL_TIM_PWM_Init(&htim1) != HAL_OK)
  {
    Error_Handler();
  }
  sMasterConfig.MasterOutputTrigger = TIM_TRGO_UPDATE;
  sMasterConfig.MasterOutputTrigger2 = TIM_TRGO2_OC5REF;
  sMasterConfig.MasterSlaveMode = TIM_MASTERSLAVEMODE_DISABLE;
  if (HAL_TIMEx_MasterConfigSynchronization(&htim1, &sMasterConfig) != HAL_OK)
  {
    Error_Handler();
  }
  sBreakInputConfig.Source = TIM_BREAKINPUTSOURCE_COMP5;
  sBreakInputConfig.Enable = TIM_BREAKINPUTSOURCE_ENABLE;
  sBreakInputConfig.Polarity = TIM_BREAKINPUTSOURCE_POLARITY_HIGH;

  if (HAL_TIMEx_ConfigBreakInput(&htim1, TIM_BREAKINPUT_BRK, &sBreakInputConfig) != HAL_OK)
  {
    Error_Handler();
  }
  sConfigOC.OCMode = TIM_OCMODE_PWM1;
  sConfigOC.Pulse = 0;
  sConfigOC.OCPolarity = TIM_OCPOLARITY_HIGH;
  sConfigOC.OCNPolarity = TIM_OCNPOLARITY_HIGH;
  sConfigOC.OCFastMode = TIM_OCFAST_DISABLE;
  sConfigOC.OCIdleState = TIM_OCIDLESTATE_RESET;
  sConfigOC.OCNIdleState = TIM_OCNIDLESTATE_RESET;
  if (HAL_TIM_PWM_ConfigChannel(&htim1, &sConfigOC, TIM_CHANNEL_1) != HAL_OK)
  {
    Error_Handler();
  }
  sConfigOC.Pulse = 1;
  if (HAL_TIM_PWM_ConfigChannel(&htim1, &sConfigOC, TIM_CHANNEL_5) != HAL_OK)
  {
    Error_Handler();
  }
  sBreakDeadTimeConfig.OffStateRunMode = TIM_OSSR_DISABLE;
  sBreakDeadTimeConfig.OffStateIDLEMode = TIM_OSSI_DISABLE;
  sBreakDeadTimeConfig.LockLevel = TIM_LOCKLEVEL_OFF;
  sBreakDeadTimeConfig.DeadTime = 0;
  sBreakDeadTimeConfig.BreakState = TIM_BREAK_DISABLE;
  sBreakDeadTimeConfig.BreakPolarity = TIM_BREAKPOLARITY_HIGH;
  sBreakDeadTimeConfig.BreakFilter = 0;
  sBreakDeadTimeConfig.BreakAFMode = TIM_BREAK_AFMODE_INPUT;
  sBreakDeadTimeConfig.Break2State = TIM_BREAK2_DISABLE;
  sBreakDeadTimeConfig.Break2Polarity = TIM_BREAK2POLARITY_HIGH;
  sBreakDeadTimeConfig.Break2Filter = 0;
  sBreakDeadTimeConfig.Break2AFMode = TIM_BREAK_AFMODE_INPUT;
  sBreakDeadTimeConfig.AutomaticOutput = TIM_AUTOMATICOUTPUT_DISABLE;
  if (HAL_TIMEx_ConfigBreakDeadTime(&htim1, &sBreakDeadTimeConfig) != HAL_OK)
  {
    Error_Handler();
  }
  HAL_TIM_MspPostInit(&htim1);

}

static void MX_TIM2_Init(void)
{

  TIM_ClockConfigTypeDef sClockSourceConfig = {0};
  TIM_MasterConfigTypeDef sMasterConfig = {0};

  htim2.Instance = TIM2;
  htim2.Init.Prescaler = 0;
  htim2.Init.CounterMode = TIM_COUNTERMODE_UP;
  htim2.Init.Period = 4294967295;
  htim2.Init.ClockDivision = TIM_CLOCKDIVISION_DIV1;
  htim2.Init.AutoReloadPreload = TIM_AUTORELOAD_PRELOAD_DISABLE;
  if (HAL_TIM_Base_Init(&htim2) != HAL_OK)
  {
    Error_Handler();
  }
  sClockSourceConfig.ClockSource = TIM_CLOCKSOURCE_INTERNAL;
  if (HAL_TIM_ConfigClockSource(&htim2, &sClockSourceConfig) != HAL_OK)
  {
    Error_Handler();
  }
  sMasterConfig.MasterOutputTrigger = TIM_TRGO_UPDATE;
  sMasterConfig.MasterSlaveMode = TIM_MASTERSLAVEMODE_DISABLE;
  if (HAL_TIMEx_MasterConfigSynchronization(&htim2, &sMasterConfig) != HAL_OK)
  {
    Error_Handler();
  }

}

static void MX_TIM6_Init(void)
{

  TIM_MasterConfigTypeDef sMasterConfig = {0};

  htim6.Instance = TIM6;
  htim6.Init.Prescaler = 170;
  htim6.Init.CounterMode = TIM_COUNTERMODE_UP;
  htim6.Init.Period = 10000;
  htim6.Init.AutoReloadPreload = TIM_AUTORELOAD_PRELOAD_DISABLE;
  if (HAL_TIM_Base_Init(&htim6) != HAL_OK)
  {
    Error_Handler();
  }
  sMasterConfig.MasterOutputTrigger = TIM_TRGO_UPDATE;
  sMasterConfig.MasterSlaveMode = TIM_MASTERSLAVEMODE_DISABLE;
  if (HAL_TIMEx_MasterConfigSynchronization(&htim6, &sMasterConfig) != HAL_OK)
  {
    Error_Handler();
  }

}

static void MX_TIM7_Init(void)
{

  TIM_MasterConfigTypeDef sMasterConfig = {0};

  htim7.Instance = TIM7;
  htim7.Init.Prescaler = 50000;
  htim7.Init.CounterMode = TIM_COUNTERMODE_UP;
  htim7.Init.Period = 1360;
  htim7.Init.AutoReloadPreload = TIM_AUTORELOAD_PRELOAD_DISABLE;
  if (HAL_TIM_Base_Init(&htim7) != HAL_OK)
  {
    Error_Handler();
  }
  sMasterConfig.MasterOutputTrigger = TIM_TRGO_UPDATE;
  sMasterConfig.MasterSlaveMode = TIM_MASTERSLAVEMODE_DISABLE;
  if (HAL_TIMEx_MasterConfigSynchronization(&htim7, &sMasterConfig) != HAL_OK)
  {
    Error_Handler();
  }

}

static void MX_TIM16_Init(void)
{

  htim16.Instance = TIM16;
  htim16.Init.Prescaler = 170;
  htim16.Init.CounterMode = TIM_COUNTERMODE_UP;
  htim16.Init.Period = 65535;
  htim16.Init.ClockDivision = TIM_CLOCKDIVISION_DIV1;
  htim16.Init.RepetitionCounter = 0;
  htim16.Init.AutoReloadPreload = TIM_AUTORELOAD_PRELOAD_DISABLE;
  if (HAL_TIM_Base_Init(&htim16) != HAL_OK)
  {
    Error_Handler();
  }

}

static void MX_USART3_UART_Init(void)
{

  huart3.Instance = USART3;
  huart3.Init.BaudRate = 115200;
  huart3.Init.WordLength = UART_WORDLENGTH_8B;
  huart3.Init.StopBits = UART_STOPBITS_1;
  huart3.Init.Parity = UART_PARITY_NONE;
  huart3.Init.Mode = UART_MODE_TX_RX;
  huart3.Init.HwFlowCtl = UART_HWCONTROL_NONE;
  huart3.Init.OverSampling = UART_OVERSAMPLING_16;
  huart3.Init.OneBitSampling = UART_ONE_BIT_SAMPLE_DISABLE;
  huart3.Init.ClockPrescaler = UART_PRESCALER_DIV1;
  huart3.AdvancedInit.AdvFeatureInit = UART_ADVFEATURE_NO_INIT;
  if (HAL_UART_Init(&huart3) != HAL_OK)
  {
    Error_Handler();
  }
  if (HAL_UARTEx_SetTxFifoThreshold(&huart3, UART_TXFIFO_THRESHOLD_1_8) != HAL_OK)
  {
    Error_Handler();
  }
  if (HAL_UARTEx_SetRxFifoThreshold(&huart3, UART_RXFIFO_THRESHOLD_1_8) != HAL_OK)
  {
    Error_Handler();
  }
  if (HAL_UARTEx_DisableFifoMode(&huart3) != HAL_OK)
  {
    Error_Handler();
  }

}

static void MX_DMA_Init(void)
{

  /* DMA controller clock enable */
  __HAL_RCC_DMAMUX1_CLK_ENABLE();
  __HAL_RCC_DMA1_CLK_ENABLE();

  /* DMA interrupt init */
  /* DMA1_Channel1_IRQn interrupt configuration */
  HAL_NVIC_SetPriority(DMA1_Channel1_IRQn, 0, 0);
  HAL_NVIC_EnableIRQ(DMA1_Channel1_IRQn);
  /* DMA1_Channel2_IRQn interrupt configuration */
  HAL_NVIC_SetPriority(DMA1_Channel2_IRQn, 0, 0);
  HAL_NVIC_EnableIRQ(DMA1_Channel2_IRQn);
  /* DMA1_Channel3_IRQn interrupt configuration */
  HAL_NVIC_SetPriority(DMA1_Channel3_IRQn, 0, 0);
  HAL_NVIC_EnableIRQ(DMA1_Channel3_IRQn);
  /* DMA1_Channel4_IRQn interrupt configuration */
  HAL_NVIC_SetPriority(DMA1_Channel4_IRQn, 0, 0);
  HAL_NVIC_EnableIRQ(DMA1_Channel4_IRQn);
  /* DMA1_Channel6_IRQn interrupt configuration */
  HAL_NVIC_SetPriority(DMA1_Channel6_IRQn, 0, 0);
  HAL_NVIC_EnableIRQ(DMA1_Channel6_IRQn);

}

static void MX_GPIO_Init(void)
{
  GPIO_InitTypeDef GPIO_InitStruct = {0};

  /* GPIO Ports Clock Enable */
  __HAL_RCC_GPIOC_CLK_ENABLE();
  __HAL_RCC_GPIOF_CLK_ENABLE();
  __HAL_RCC_GPIOA_CLK_ENABLE();
  __HAL_RCC_GPIOB_CLK_ENABLE();

  /*Configure GPIO pin Output Level */
  HAL_GPIO_WritePin(LED4_GPIO_Port, LED4_Pin, GPIO_PIN_RESET);

  /*Configure GPIO pin Output Level */
  HAL_GPIO_WritePin(GPIOA, CN2_Pin|CN1_Pin|BLED1_Pin|BLED2_Pin
                          |BLED3_Pin, GPIO_PIN_RESET);

  /*Configure GPIO pin Output Level */
  HAL_GPIO_WritePin(GPIOB, STOP_Pin|LED1_Pin|LED2_Pin|LED3_Pin, GPIO_PIN_RESET);

  /*Configure GPIO pin : LED4_Pin */
  GPIO_InitStruct.Pin = LED4_Pin;
  GPIO_InitStruct.Mode = GPIO_MODE_OUTPUT_PP;
  GPIO_InitStruct.Pull = GPIO_NOPULL;
  GPIO_InitStruct.Speed = GPIO_SPEED_FREQ_LOW;
  HAL_GPIO_Init(LED4_GPIO_Port, &GPIO_InitStruct);

  /*Configure GPIO pins : CN2_Pin CN1_Pin BLED1_Pin BLED2_Pin
                           BLED3_Pin */
  GPIO_InitStruct.Pin = CN2_Pin|CN1_Pin|BLED1_Pin|BLED2_Pin
                          |BLED3_Pin;
  GPIO_InitStruct.Mode = GPIO_MODE_OUTPUT_PP;
  GPIO_InitStruct.Pull = GPIO_NOPULL;
  GPIO_InitStruct.Speed = GPIO_SPEED_FREQ_LOW;
  HAL_GPIO_Init(GPIOA, &GPIO_InitStruct);

  /*Configure GPIO pin : INT_IN_Pin */
  GPIO_InitStruct.Pin = INT_IN_Pin;
  GPIO_InitStruct.Mode = GPIO_MODE_IT_RISING;
  GPIO_InitStruct.Pull = GPIO_NOPULL;
  HAL_GPIO_Init(INT_IN_GPIO_Port, &GPIO_InitStruct);

  /*Configure GPIO pins : STOP_Pin LED1_Pin LED2_Pin LED3_Pin */
  GPIO_InitStruct.Pin = STOP_Pin|LED1_Pin|LED2_Pin|LED3_Pin;
  GPIO_InitStruct.Mode = GPIO_MODE_OUTPUT_PP;
  GPIO_InitStruct.Pull = GPIO_NOPULL;
  GPIO_InitStruct.Speed = GPIO_SPEED_FREQ_LOW;
  HAL_GPIO_Init(GPIOB, &GPIO_InitStruct);

  /* EXTI interrupt init*/
  HAL_NVIC_SetPriority(EXTI2_IRQn, 0, 0);
  HAL_NVIC_EnableIRQ(EXTI2_IRQn);

}

void Error_Handler(void)
{
  __disable_irq();
  while (1)
  {
  }
}
